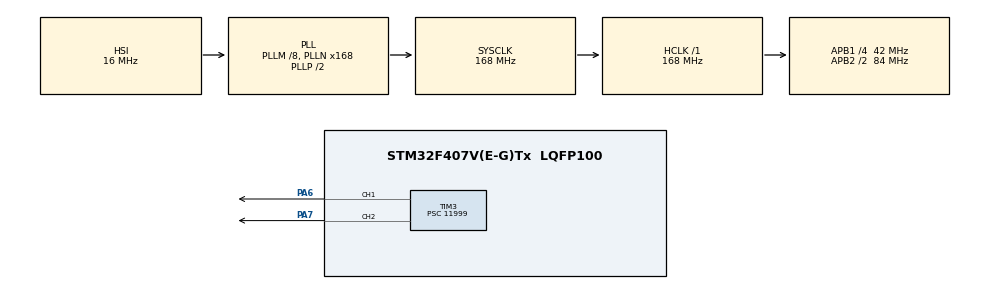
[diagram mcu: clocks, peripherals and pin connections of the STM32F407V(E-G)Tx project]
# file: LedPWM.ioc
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Dma.Request0=TIM3_CH1/TRIG
Dma.Request1=TIM3_CH2
Dma.TIM3_CH1/TRIG.0.Direction=DMA_PERIPH_TO_MEMORY
Dma.TIM3_CH1/TRIG.0.FIFOMode=DMA_FIFOMODE_DISABLE
Dma.TIM3_CH1/TRIG.0.Instance=DMA1_Stream4
Dma.TIM3_CH1/TRIG.0.MemDataAlignment=DMA_MDATAALIGN_HALFWORD
Dma.TIM3_CH1/TRIG.0.MemInc=DMA_MINC_ENABLE
Dma.TIM3_CH1/TRIG.0.Mode=DMA_CIRCULAR
Dma.TIM3_CH1/TRIG.0.PeriphDataAlignment=DMA_PDATAALIGN_HALFWORD
Dma.TIM3_CH1/TRIG.0.PeriphInc=DMA_PINC_DISABLE
Dma.TIM3_CH1/TRIG.0.Priority=DMA_PRIORITY_LOW
Dma.TIM3_CH2.1.Direction=DMA_PERIPH_TO_MEMORY
Dma.TIM3_CH2.1.FIFOMode=DMA_FIFOMODE_DISABLE
Dma.TIM3_CH2.1.Instance=DMA1_Stream5
Dma.TIM3_CH2.1.MemDataAlignment=DMA_MDATAALIGN_HALFWORD
Dma.TIM3_CH2.1.MemInc=DMA_MINC_ENABLE
Dma.TIM3_CH2.1.Mode=DMA_CIRCULAR
Dma.TIM3_CH2.1.PeriphDataAlignment=DMA_PDATAALIGN_HALFWORD
Dma.TIM3_CH2.1.PeriphInc=DMA_PINC_DISABLE
Dma.TIM3_CH2.1.Priority=DMA_PRIORITY_LOW
Mcu.Family=STM32F4
Mcu.Name=STM32F407V(E-G)Tx
Mcu.Package=LQFP100
NVIC.DMA1_Stream4_IRQn=true\:0\:0\:false\:false\:true\:false\:true\:true
NVIC.DMA1_Stream5_IRQn=true\:0\:0\:false\:false\:true\:false\:true\:true
NVIC.PriorityGroup=NVIC_PRIORITYGROUP_4
PA13.Mode=Serial_Wire
PA13.Signal=SYS_JTMS-SWDIO
PA14.Mode=Serial_Wire
PA14.Signal=SYS_JTCK-SWCLK
PA6.Signal=S_TIM3_CH1
PA7.Signal=S_TIM3_CH2
PH0-OSC_IN.Mode=HSE-External-Oscillator
PH0-OSC_IN.Signal=RCC_OSC_IN
PH1-OSC_OUT.Mode=HSE-External-Oscillator
PH1-OSC_OUT.Signal=RCC_OSC_OUT
ProjectManager.HeapSize=0x200
ProjectManager.StackSize=0x400
ProjectManager.TargetToolchain=STM32CubeIDE
RCC.48MHZClocksFreq_Value=84000000
RCC.AHBFreq_Value=168000000
RCC.APB1CLKDivider=RCC_HCLK_DIV4
RCC.APB1Freq_Value=42000000
RCC.APB1TimFreq_Value=84000000
RCC.APB2CLKDivider=RCC_HCLK_DIV2
RCC.APB2Freq_Value=84000000
RCC.APB2TimFreq_Value=168000000
RCC.CortexFreq_Value=168000000
RCC.HCLKFreq_Value=168000000
RCC.HSE_VALUE=25000000
RCC.HSI_VALUE=16000000
RCC.LSE_VALUE=32768
RCC.PLLM=8
RCC.PLLN=168
RCC.SYSCLKFreq_VALUE=168000000
RCC.SYSCLKSource=RCC_SYSCLKSOURCE_PLLCLK
RCC.VCOOutputFreq_Value=336000000
SH.S_TIM3_CH1.0=TIM3_CH1,PWM Generation1 CH1
SH.S_TIM3_CH2.0=TIM3_CH2,PWM Generation2 CH2
TIM3.Channel-PWM\ Generation1\ CH1=TIM_CHANNEL_1
TIM3.Channel-PWM\ Generation2\ CH2=TIM_CHANNEL_2
TIM3.Period=100
TIM3.Prescaler=11999
TIM3.Pulse-PWM\ Generation1\ CH1=10
TIM3.Pulse-PWM\ Generation2\ CH2=90
board=custom

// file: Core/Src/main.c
/* USER CODE BEGIN Header */
/**
  ******************************************************************************
  * @file           : main.c
  * @brief          : Main program body
  ******************************************************************************
  * @attention
  *
  * Copyright (c) 2025 STMicroelectronics.
  * All rights reserved.
  *
  * This software is licensed under terms that can be found in the LICENSE file
  * in the root directory of this software component.
  * If no LICENSE file comes with this software, it is provided AS-IS.
  *
  ******************************************************************************
  */
/* USER CODE END Header */
#include "main.h"

TIM_HandleTypeDef htim3;
DMA_HandleTypeDef hdma_tim3_ch1_trig;
DMA_HandleTypeDef hdma_tim3_ch2;

void SystemClock_Config(void);
static void MX_GPIO_Init(void);
static void MX_DMA_Init(void);
static void MX_TIM3_Init(void);
/* USER CODE BEGIN PFP */
void init();
void loop();
/* USER CODE END PFP */

/* USER CODE BEGIN 0 */
void init()
{
//	HAL_TIM_PWM_Start(&htim3, TIM_CHANNEL_1);
//	HAL_TIM_PWM_Start(&htim3, TIM_CHANNEL_2);

	uint32_t tim3ch1[200];
	for (uint32_t i = 0; i < 100; ++i)
	{
		tim3ch1[i] = i;
		tim3ch1[i + 100] = 99 - i;
	}
	HAL_TIM_PWM_Start_DMA(&htim3, TIM_CHANNEL_1, tim3ch1, 200);
//	HAL_Delay(1500);
	HAL_TIM_PWM_Start_DMA(&htim3, TIM_CHANNEL_2, tim3ch1, 200);

	return;
}

void loop()
{
#if 1
	for (uint16_t i = 0; i <= 100; ++i)
	{
		TIM3->CCR1 = 100 - i;
		__HAL_TIM_SET_COMPARE(&htim3, TIM_CHANNEL_2, i);
		HAL_Delay(5);
	}
#endif // SIMPLE_PWM

	HAL_Delay(100);
	return;
}
/* USER CODE END 0 */

int main(void)
{

  /* MCU Configuration--------------------------------------------------------*/

  /* Reset of all peripherals, Initializes the Flash interface and the Systick. */
  HAL_Init();

  /* Configure the system clock */
  SystemClock_Config();

  /* Initialize all configured peripherals */
  MX_GPIO_Init();
  MX_DMA_Init();
  MX_TIM3_Init();
  /* USER CODE BEGIN 2 */
  init();

  /* USER CODE END 2 */

  /* Infinite loop */
  /* USER CODE BEGIN WHILE */
  while (1)
  {
	loop();
    /* USER CODE END WHILE */

  }
}

void SystemClock_Config(void)
{
  RCC_OscInitTypeDef RCC_OscInitStruct = {0};
  RCC_ClkInitTypeDef RCC_ClkInitStruct = {0};

  /** Configure the main internal regulator output voltage
  */
  __HAL_RCC_PWR_CLK_ENABLE();
  __HAL_PWR_VOLTAGESCALING_CONFIG(PWR_REGULATOR_VOLTAGE_SCALE1);

  /** Initializes the RCC Oscillators according to the specified parameters
  * in the RCC_OscInitTypeDef structure.
  */
  RCC_OscInitStruct.OscillatorType = RCC_OSCILLATORTYPE_HSI;
  RCC_OscInitStruct.HSIState = RCC_HSI_ON;
  RCC_OscInitStruct.HSICalibrationValue = RCC_HSICALIBRATION_DEFAULT;
  RCC_OscInitStruct.PLL.PLLState = RCC_PLL_ON;
  RCC_OscInitStruct.PLL.PLLSource = RCC_PLLSOURCE_HSI;
  RCC_OscInitStruct.PLL.PLLM = 8;
  RCC_OscInitStruct.PLL.PLLN = 168;
  RCC_OscInitStruct.PLL.PLLP = RCC_PLLP_DIV2;
  RCC_OscInitStruct.PLL.PLLQ = 4;
  if (HAL_RCC_OscConfig(&RCC_OscInitStruct) != HAL_OK)
  {
    Error_Handler();
  }

  /** Initializes the CPU, AHB and APB buses clocks
  */
  RCC_ClkInitStruct.ClockType = RCC_CLOCKTYPE_HCLK|RCC_CLOCKTYPE_SYSCLK
                              |RCC_CLOCKTYPE_PCLK1|RCC_CLOCKTYPE_PCLK2;
  RCC_ClkInitStruct.SYSCLKSource = RCC_SYSCLKSOURCE_PLLCLK;
  RCC_ClkInitStruct.AHBCLKDivider = RCC_SYSCLK_DIV1;
  RCC_ClkInitStruct.APB1CLKDivider = RCC_HCLK_DIV4;
  RCC_ClkInitStruct.APB2CLKDivider = RCC_HCLK_DIV2;

  if (HAL_RCC_ClockConfig(&RCC_ClkInitStruct, FLASH_LATENCY_5) != HAL_OK)
  {
    Error_Handler();
  }
}

static void MX_TIM3_Init(void)
{

  TIM_MasterConfigTypeDef sMasterConfig = {0};
  TIM_OC_InitTypeDef sConfigOC = {0};

  htim3.Instance = TIM3;
  htim3.Init.Prescaler = 11999;
  htim3.Init.CounterMode = TIM_COUNTERMODE_UP;
  htim3.Init.Period = 100;
  htim3.Init.ClockDivision = TIM_CLOCKDIVISION_DIV1;
  htim3.Init.AutoReloadPreload = TIM_AUTORELOAD_PRELOAD_DISABLE;
  if (HAL_TIM_PWM_Init(&htim3) != HAL_OK)
  {
    Error_Handler();
  }
  sMasterConfig.MasterOutputTrigger = TIM_TRGO_RESET;
  sMasterConfig.MasterSlaveMode = TIM_MASTERSLAVEMODE_DISABLE;
  if (HAL_TIMEx_MasterConfigSynchronization(&htim3, &sMasterConfig) != HAL_OK)
  {
    Error_Handler();
  }
  sConfigOC.OCMode = TIM_OCMODE_PWM1;
  sConfigOC.Pulse = 10;
  sConfigOC.OCPolarity = TIM_OCPOLARITY_HIGH;
  sConfigOC.OCFastMode = TIM_OCFAST_DISABLE;
  if (HAL_TIM_PWM_ConfigChannel(&htim3, &sConfigOC, TIM_CHANNEL_1) != HAL_OK)
  {
    Error_Handler();
  }
  sConfigOC.Pulse = 90;
  if (HAL_TIM_PWM_ConfigChannel(&htim3, &sConfigOC, TIM_CHANNEL_2) != HAL_OK)
  {
    Error_Handler();
  }
  HAL_TIM_MspPostInit(&htim3);

}

static void MX_DMA_Init(void)
{

  /* DMA controller clock enable */
  __HAL_RCC_DMA1_CLK_ENABLE();

  /* DMA interrupt init */
  /* DMA1_Stream4_IRQn interrupt configuration */
  HAL_NVIC_SetPriority(DMA1_Stream4_IRQn, 0, 0);
  HAL_NVIC_EnableIRQ(DMA1_Stream4_IRQn);
  /* DMA1_Stream5_IRQn interrupt configuration */
  HAL_NVIC_SetPriority(DMA1_Stream5_IRQn, 0, 0);
  HAL_NVIC_EnableIRQ(DMA1_Stream5_IRQn);

}

static void MX_GPIO_Init(void)
{

  /* GPIO Ports Clock Enable */
  __HAL_RCC_GPIOH_CLK_ENABLE();
  __HAL_RCC_GPIOA_CLK_ENABLE();

}

void Error_Handler(void)
{
  __disable_irq();
  while (1)
  {
  }
}
